AUTOSAR XML (schema 4-2-2)
package /Composition1
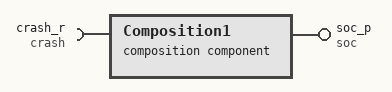
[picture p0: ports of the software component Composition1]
  composition sw component type Composition1
    provide port soc_p: provided-interface=soc
    require port crash_r: required-interface=crash
    component CPT_ComM: type=ComM
    component CPT_swc: type=swc
    delegate CPT_swc.soc_p <-> outer port soc_p
    delegate CPT_swc.crash_r <-> outer port crash_r
